# Queue_MGR register map
Vendor: Texas Instruments
Peripheral module from a debugger description file (folder am335x).
Registers are 32-bit, read-only, no defined reset value unless marked. A register's access mark holds for its fields unless they carry their own. Offsets are as the file gives them; lines under a group give offsets from that group; [hi:lo] are bit positions; {n}, {i} and the like mark numbered series; 'fields as' and 'values as' point back to an identical list; <NAME> marks a mode.

## Queue_MGR
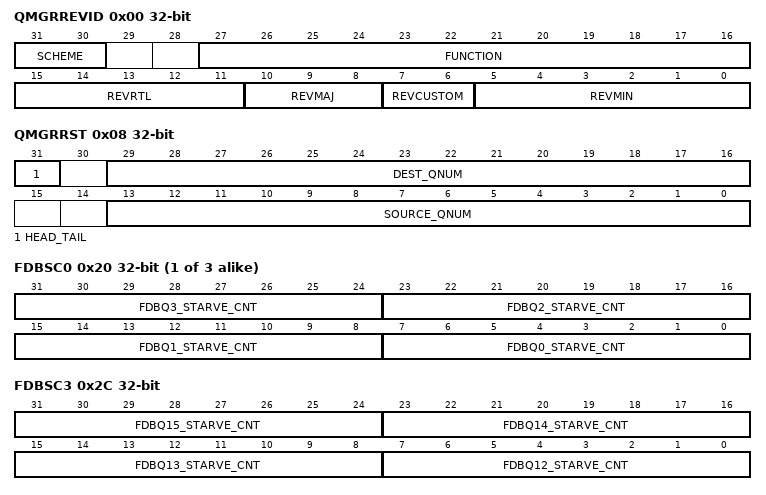
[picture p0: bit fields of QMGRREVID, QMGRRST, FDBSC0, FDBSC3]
0x00 QMGRREVID
  [31:30] SCHEME — Scheme that this register is compliant with
  [27:16] FUNCTION
  [15:11] REVRTL — RTL revision
  [10:8] REVMAJ — Major revision
  [7:6] REVCUSTOM — Custom revision
  [5:0] REVMIN — Minor revision Queue Manager Revision Register
0x08 QMGRRST wo
  [31] HEAD_TAIL — Indicates whether queue contents should be merged on to head or tail of destination queue. Clear this field for head and set for tail.
  [29:16] DEST_QNUM — Destination Queue Number
  [13:0] SOURCE_QNUM — Source Queue Number Queue Manager Queue Diversion Register Note : CBA write transactions to this register cause the QMGR to start processing an internal state machine. This disables CBA read transactions.while it is busy processing the state machine. Once the state machine is back in the idle state ; CBA read transactions are available again.
{0x20+4i} FDBSC{i} (i=0..2)
  [31:24] FDBQ{4i+3}_STARVE_CNT — This field increments each time the Free Descriptor/Buffer Queue {4i+3} is read while it is empty via the CPPI DMA. This field is cleared when read via the cpu.
  [23:16] FDBQ{4i+2}_STARVE_CNT — This field increments each time the Free Descriptor/Buffer Queue {4i+2} is read while it is empty via the CPPI DMA. This field is cleared when read via the cpu.
  [15:8] FDBQ{4i+1}_STARVE_CNT — This field increments each time the Free Descriptor/Buffer Queue {4i+1} is read while it is empty via the CPPI DMA. This field is cleared when read via the cpu.
  [7:0] FDBQ{4i}_STARVE_CNT — This field increments each time the Free Descriptor/Buffer Queue {4i} is read while it is empty via the CPPI DMA. This field is cleared when read via the cpu. Queue_Manager_Free_Descriptor_Buffer_Starvation_Count Register {i}
0x2C FDBSC3
  [31:24] FDBQ15_STARVE_CNT — This field increments each time the Free Descriptor/Buffer Queue 15 is read while it is empty via the CPPI DMA. This field is cleared when read via the cpu.
  [23:16] FDBQ14_STARVE_CNT — This field increments each time the Free Descriptor/Buffer Queue 14 is read while it is empty via the CPPI DMA. This field is cleared when read via the cpu.
  [15:8] FDBQ13_STARVE_CNT — This field increments each time the Free Descriptor/Buffer Queue 13 is read while it is empty via the CPPI DMA. This field is cleared when read via the cpu.
  [7:0] FDBQ12_STARVE_CNT — This field increments each time the Free Descriptor/Buffer Queue 12 is read while it is empty via the CPPI DMA. This field is cleared when read via the cpu. Table 109 - QMGR_Free_Descriptor_Buffer_Starvation_Count Register 3
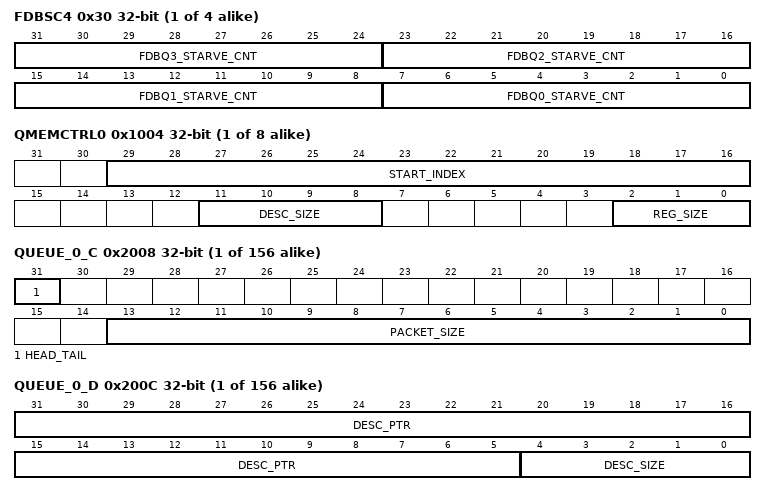
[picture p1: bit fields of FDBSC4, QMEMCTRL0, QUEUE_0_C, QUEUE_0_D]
{0x20+4i} FDBSC{i} (i=4..7)
  fields as FDBSC0
0x80 LRAM0BASE rw
  [31:2] REGION0_BASE — This field stores the base address for the first region of the linking RAM. This may be anywhere in 32-bit address space but would be typically located in on-chip memory.
0x84 LRAM0SIZE rw
  [13:0] REGION0_SIZE — This field indicates the number of entries that are contained in the linking RAM region 0. A descriptor with index less than region0_size value has its linking location in region 0. A descriptor with index greater than region0_size has its linking location in region 1. The queue manager will add the index (left shifted by 2 bits) to the appropriate regionX_base_addr to get the absolute 32-bit address to the linking location for a descriptor. Queue Manager Linking Ram Region 0 Size Register
0x88 LRAM1BASE rw
  [31:2] REGION1_BASE — This field stores the base address for the second region of the linking RAM. This may be anywhere in 32- bit address space but would be typically located in off- chip memory.
0x90 PEND0
  [31:0] QPEND0 — This field indicates the queue pending status for queues[31:0].
0x94 PEND1
  [31:0] QPEND1 — This field indicates the queue pending status for queues[63:32]. Table 118 - QMGR_Queue_Pending_1 Register 1
{0x90+4i} PEND{i} (i=2..4)
  [31:0] QPEND{i} — This field indicates the queue pending status for queues[{32i+31}:{32i}]. Queue_Manager_Queue_Pending_{i} Register {i}
{0x1000+0x10*i} QMEMRBASE{i} rw (i=0..7)
  [31:5] REG — This field contains the base address of the memory region R.
{0x1004+0x10*i} QMEMCTRL{i} rw (i=0..7)
  [29:16] START_INDEX — This field indicates where in linking RAM does the descriptor linking information corresponding to memory region R starts.
  [11:8] DESC_SIZE — This field indicates the size of each descriptor in this memory region. It is an encoded value that specifies descriptor size as 2^(5+desc_size) number of bytes. The settings of desc_size from 9-15 are reserved.
  [2:0] REG_SIZE — This field indicates the size of the memory region (in terms of number of descriptors). It is an encoded value that specifies region size as 2^(5+reg_size) number of descriptors. Queue Manager Memory Region R Control Registers The following sections describe each of the four register locations that may be present for each queue in the queues region. For reasons of implementation and area efficiency, these registers are not actually implemented as a huge array of flip flops but are instead implemented as a single set of mailbox registers which use the LSBs of the provided address as a queue index. Due to this implementation all accesses to these registers need to be performed as a single burst write for each packet push operation or a single burst read for each packet pop operation. The length of a burst to push or pop a packet will vary depending on the optional features that the queue supports which may be 4, 8, 12 or 16 bytes. Queue N Register D must always be written / read in the burst but the preceding words are optional depending on the required queue functionality.
{0x2000+0x10*i} QUEUE_{i}_A (i=0..155)
  [13:0] QUEUE_ENTRY_COUNT — This field indicates how many packets are currently queued on the queue. This count is incremented by 1 whenever a packet is added to the queue. This count is decremented by 1 whenever a packet is popped from the queue.
{0x2004+0x10*i} QUEUE_{i}_B (i=0..155)
  [27:0] QUEUE_BYTE_COUNT — This field indicates how many bytes total are contained in all of the packets which are currently queued on this queue.
{0x2008+0x10*i} QUEUE_{i}_C access per field (i=0..155)
  [31] HEAD_TAIL wo — Head/Tail Push Control. Set to zero in order to push packet onto tail of queue and set to one in order to push packet onto head of queue.
  [13:0] PACKET_SIZE rw — packet_size This field indicates packet size and is assumed to be zero on each packet add unless the value is explicitly overwritten. This field indicates packet size for packet pop operation.
{0x200C+0x10*i} QUEUE_{i}_D rw (i=0..155)
  [31:5] DESC_PTR — Descriptor pointer. It will be read as zero if the queue is empty. It will indicate a 32-bit aligned address that points to a descriptor when the queue is not empty.
  [4:0] DESC_SIZE — Descriptor Size. It is encoded in 4-byte increments with values 0 to 31 representing 24 and so on to 148 bytes. This field will return a 0x0 when an empty queue is read. Queue Manager Queue N Registers D To save hardware resources, the queue manager internally stores descriptor size (desc_size) information in four bits. However, register D has five LSBs that specify descriptor size. As a consequence, the value of desc_size that is pushed may not be same as that is read during a pop. The value that is read back is equal to always rounded to an odd number. So, for even values, the value read back is one more than what was written. For odd values, the value read back is same as the value that was written. Note that this 5-bit field (desc_size) is unrelated to the code for size of descriptors in a descriptor region. It is just a place holder for a 5-bit value that is maintained across the push and pop operations for every descriptor managed by the queue manager.
{0x3000+0x10*i} QUEUE_{i}_STATUS_A (i=0..155)
  [13:0] QUEUE_ENTRY_COUNT — This field indicates how many packets are currently queued on the queue. Queue Manager Queue N Status Registers A
{0x3004+0x10*i} QUEUE_{i}_STATUS_B (i=0..155)
  [27:0] QUEUE_BYTE_COUNT — This field indicates how many bytes total are contained in all of the packets which are currently queued on this queue. Queue_Manager_Queue_n_Status_B Registers B
{0x3008+0x10*i} QUEUE_{i}_STATUS_C (i=0..155)
  [13:0] PACKET_SIZE — This field indicates packet size of the head element of a queue. Queue_Manager_Queue_N_Status_C Registers C
